# EZR32LG230F256R63 register map
File version: 5.8.2
CPU: CM3 r2p1, little endian, MPU, no FPU, 3 interrupt priority bits
Registers are 32-bit, read-write, reset 0x0 unless marked. A register's access mark holds for its fields unless they carry their own. Offsets are from the block's base; [hi:lo] are bit positions; {n}, {i} and the like mark numbered series.

## LETIMER0
Base 0x40082000
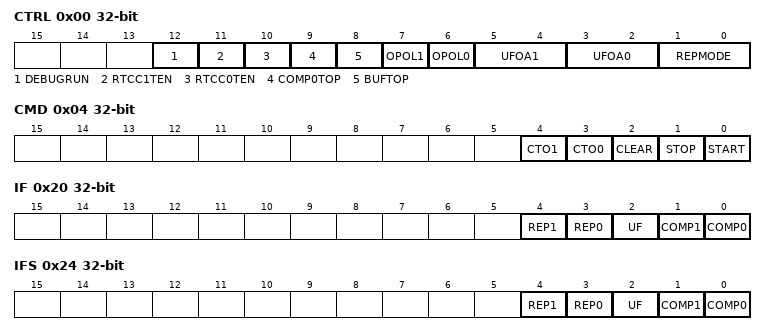
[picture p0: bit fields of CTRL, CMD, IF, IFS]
0x00 CTRL — Control Register
  [12] DEBUGRUN — Debug Mode Run Enable
  [11] RTCC1TEN — RTC Compare 1 Trigger Enable
  [10] RTCC0TEN — RTC Compare 0 Trigger Enable
  [9] COMP0TOP — Compare Value 0 Is Top Value
  [8] BUFTOP — Buffered Top
  [7] OPOL1 — Output 1 Polarity
  [6] OPOL0 — Output 0 Polarity
  [5:4] UFOA1 — Underflow Output Action 1
    0=NONE (LETn_O1 is held at its idle value as defined by OPOL1.); 1=TOGGLE (LETn_O1 is toggled on CNT underflow.); 2=PULSE (LETn_O1 is held active for one LFACLKLETIMER0 clock cycle on CNT underflow. The output then returns to its idle value as defined by OPOL1.); 3=PWM (LETn_O1 is set idle on CNT underflow, and active on compare match with COMP1)
  [3:2] UFOA0 — Underflow Output Action 0
    0=NONE (LETn_O0 is held at its idle value as defined by OPOL0.); 1=TOGGLE (LETn_O0 is toggled on CNT underflow.); 2=PULSE (LETn_O0 is held active for one LFACLKLETIMER0 clock cycle on CNT underflow. The output then returns to its idle value as defined by OPOL0.); 3=PWM (LETn_O0 is set idle on CNT underflow, and active on compare match with COMP1)
  [1:0] REPMODE — Repeat Mode
    0=FREE (When started, the LETIMER counts down until it is stopped by software.); 1=ONESHOT (The counter counts REP0 times. When REP0 reaches zero, the counter stops.); 2=BUFFERED (The counter counts REP0 times. If REP1 has been written, it is loaded into REP0 when REP0 reaches zero. Else the counter stops); 3=DOUBLE (Both REP0 and REP1 are decremented when the LETIMER wraps around. The LETIMER counts until both REP0 and REP1 are zero)
0x04 CMD wo — Command Register
  [4] CTO1 — Clear Toggle Output 1
  [3] CTO0 — Clear Toggle Output 0
  [2] CLEAR — Clear LETIMER
  [1] STOP — Stop LETIMER
  [0] START — Start LETIMER
0x08 STATUS ro
  [0] RUNNING — LETIMER Running
0x0C CNT — Counter Value Register
  [15:0] CNT — Counter Value
0x10 COMP0 — Compare Value Register 0
  [15:0] COMP0 — Compare Value 0
0x14 COMP1 — Compare Value Register 1
  [15:0] COMP1 — Compare Value 1
0x18 REP0 — Repeat Counter Register 0
  [7:0] REP0 — Repeat Counter 0
0x1C REP1 — Repeat Counter Register 1
  [7:0] REP1 — Repeat Counter 1
0x20 IF ro — Interrupt Flag Register
  [4] REP1 — Repeat Counter 1 Interrupt Flag
  [3] REP0 — Repeat Counter 0 Interrupt Flag
  [2] UF — Underflow Interrupt Flag
  [1] COMP1 — Compare Match 1 Interrupt Flag
  [0] COMP0 — Compare Match 0 Interrupt Flag
0x24 IFS wo — Interrupt Flag Set Register
  [4] REP1 — Set Repeat Counter 1 Interrupt Flag
  [3] REP0 — Set Repeat Counter 0 Interrupt Flag
  [2] UF — Set Underflow Interrupt Flag
  [1] COMP1 — Set Compare Match 1 Interrupt Flag
  [0] COMP0 — Set Compare Match 0 Interrupt Flag
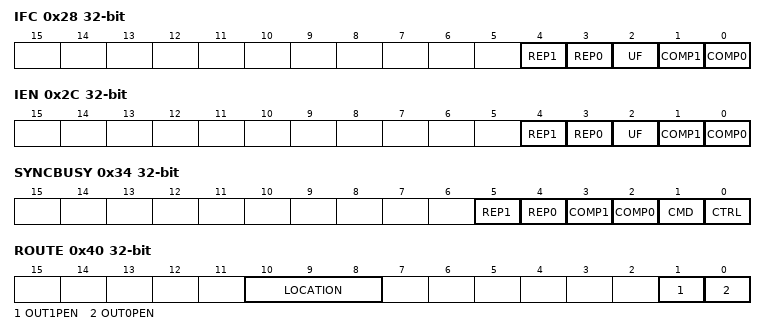
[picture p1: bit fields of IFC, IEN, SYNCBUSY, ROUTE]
0x28 IFC wo — Interrupt Flag Clear Register
  [4] REP1 — Clear Repeat Counter 1 Interrupt Flag
  [3] REP0 — Clear Repeat Counter 0 Interrupt Flag
  [2] UF — Clear Underflow Interrupt Flag
  [1] COMP1 — Clear Compare Match 1 Interrupt Flag
  [0] COMP0 — Clear Compare Match 0 Interrupt Flag
0x2C IEN — Interrupt Enable Register
  [4] REP1 — Repeat Counter 1 Interrupt Enable
  [3] REP0 — Repeat Counter 0 Interrupt Enable
  [2] UF — Underflow Interrupt Enable
  [1] COMP1 — Compare Match 1 Interrupt Enable
  [0] COMP0 — Compare Match 0 Interrupt Enable
0x30 FREEZE
  [0] REGFREEZE — Register Update Freeze
0x34 SYNCBUSY ro — Synchronization Busy Register
  [5] REP1 — REP1 Register Busy
  [4] REP0 — REP0 Register Busy
  [3] COMP1 — COMP1 Register Busy
  [2] COMP0 — COMP0 Register Busy
  [1] CMD — CMD Register Busy
  [0] CTRL — CTRL Register Busy
0x40 ROUTE — I/O Routing Register
  [10:8] LOCATION — I/O Location
    {v}=LOC{v} (Location {v}) (v=0..3)
  [1] OUT1PEN — Output 1 Pin Enable
  [0] OUT0PEN — Output 0 Pin Enable

## Notices in the file
# License
Copyright 2019 Silicon Laboratories Inc. www.silabs.com
SPDX-License-Identifier: Zlib
The licensor of this software is Silicon Laboratories Inc.
This software is provided 'as-is', without any express or implied
warranty. In no event will the authors be held liable for any damages
arising from the use of this software.
Permission is granted to anyone to use this software for any purpose,
including commercial applications, and to alter it and redistribute it
freely, subject to the following restrictions:
1. The origin of this software must not be misrepresented; you must not
claim that you wrote the original software. If you use this software
in a product, an acknowledgment in the product documentation would be
appreciated but is not required.
2. Altered source versions must be plainly marked as such, and must not be
misrepresented as being the original software.
3. This notice may not be removed or altered from any source distribution.
